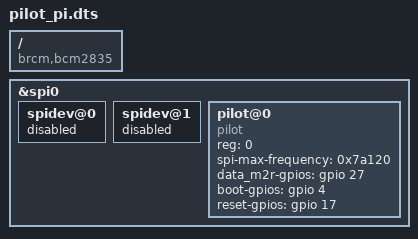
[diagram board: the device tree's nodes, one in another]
/*
 * Device Tree overlay for pilot board
 * Raspberry Pi
 */

/dts-v1/;
/plugin/;

/ {
    compatible = "brcm,bcm2835", "brcm,bcm2708", "brcm,bcm2709";
    /* disable spi-dev for spi0.0 & spi0.1 */
    fragment@0 {
	target = <&spi0>;
	__overlay__ {
		status = "okay";

		spidev@0{
			status = "disabled";
		};
		spidev@1{
			status = "disabled";
		};
	};
    };

    fragment@1 {
	target = <&spi0>;
	__overlay__ {
            #address-cells = <1>;
            #size-cells = <0>;
            pinctrl-names = "default";

            pilot@0 {
                compatible = "pilot";
                #address-cells = <0x1>;
                #size-cells = <0x0>;
                reg = <0>;      /* CE0 */
                spi-max-frequency = <0x7a120>;
				status = "okay";
				data_m2r-gpios = <&gpio 27 0>;
                boot-gpios = <&gpio 4 0>;
                reset-gpios = <&gpio 17 0>;
            };
	};
    };
};
